AUTOSAR XML (schema 4.0)
standard types defined: float32, float64, sint16, sint32, sint8, uint16, uint32, uint8, void, boolean
package /ImplDataTypes
  impl type Impl_IOPositionSensorRead: implementation-data-type=uint8, type-emitter=RTE
  impl type Impl_IOWeightSensorRead: implementation-data-type=uint16, type-emitter=RTE
  impl type Impl_StepMotorStepSize: implementation-data-type=uint8, type-emitter=RTE
package /MappingSets
  data type mapping set MappingSet
package /PortInterfaces/ClientServer
  20 x client server interface:
    CsIf_HeightMotor
      operation Opr_IOSetForward
        arg Step: type=Impl_StepMotorStepSize, direction=IN
      operation Opr_IOSetReverse
        arg Step: type=Impl_StepMotorStepSize, direction=IN
    CsIf_HeightMotorSeatManager
      operation Opr_GetPosition
        arg Arg_Position: type=Impl_IOPositionSensorRead, direction=IN
    CsIf_HeightSensor
      operation Opr_HeightSensorGetPosition
        arg Position: type=Impl_IOPositionSensorRead, direction=OUT
    CsIf_IOHwAbsHeight
      operation Opr_HeightSensorGetPosition
        arg Arg_Height: type=Impl_IOPositionSensorRead, direction=OUT
    CsIf_IOHwAbsHeightMotor
      operation Opr_HeightMotorForward
    CsIf_IOHwAbsHeightMotorReverse
      operation Opr_HeightMotorReverse
    CsIf_IOHwAbsIncline
      operation Opr_IOHwAbsIncline
        arg Arg_Incline: type=Impl_IOPositionSensorRead, direction=OUT
    CsIf_IOHwAbsInclineMotor
      operation Opr_InclineMotorForward
    CsIf_IOHwAbsInclineMotorReverse
      operation Opr_InclineMotorReverse
    CsIf_IOHwAbsSlide
      operation Opr_IOHwAbsSlide
        arg Arg_Slide: type=Impl_IOPositionSensorRead, direction=OUT
    CsIf_IOHwAbsSlideMotor
      operation Opr_SLideMotorForward
    CsIf_IOHwAbsSlideMotorReverse
      operation Opr_SlideMotorReverse
    CsIf_IOHwAbsWeight
      operation Opr_GetWeight
        arg Arg_Weight: type=Impl_IOWeightSensorRead, direction=OUT
    CsIf_InclineMotor
      operation Opr_InclineMotorIOSetForward
        arg Step: type=Impl_StepMotorStepSize, direction=IN
      operation Opr_InclineMotorIOSetReverse
        arg Step: type=Impl_StepMotorStepSize, direction=IN
    CsIf_InclineMotorSeatManager
      operation Opr_GetPosition
        arg Arg_Position: type=Impl_IOPositionSensorRead, direction=IN
    CsIf_InclineSensor
      operation Opr_InclineSensorGetPosition
        arg Arg_Position: type=uint8, direction=OUT
    CsIf_SlideMotor
      operation Opr_SlideMotorSetReverse
        arg Step: type=Impl_StepMotorStepSize, direction=IN
      operation Opr_SlideMotor_SetForrward
        arg Step: type=Impl_StepMotorStepSize, direction=IN
    CsIf_SlideMotorSeatManager
      operation Opr_GetPositon
        arg Arg_Position: type=Impl_IOPositionSensorRead, direction=IN
    CsIf_SlideSensor
      operation Opr_GetPositon
        arg Position: type=uint8, direction=OUT
    CsIf_WeightSensor
      operation Opr_GetWeight
        arg Arg_weight: type=uint16, direction=OUT
package /SoftwareComponents
  9 x swc implementation, all with programming-language=C, sw-version=1.0.0, vendor-id=255:
    Impl_SWC_HeightMotor: behavior=Ibhv_SWC_HeightMotor
      code-descriptors:
        code Code: artifact-descriptors=autosar-engineering-object={short-label=SWC.c, category=SWSRC}
      resource consumption ResourceConsumption
    Impl_SWC_HeightSensor: behavior=Ibhv_SWC_HeightSensor
      code-descriptors:
        code Code: artifact-descriptors=autosar-engineering-object={short-label=SWC.c, category=SWSRC}
      resource consumption ResourceConsumption
    Impl_SWC_IOHwAbs: behavior=Ibhv_SWC_IOHwAbs
      code-descriptors:
        code Code: artifact-descriptors=autosar-engineering-object={short-label=SWC.c, category=SWSRC}
      resource consumption ResourceConsumption
    Impl_SWC_InclineMotor: behavior=Ibhv_SWC_InclineMotor
      code-descriptors:
        code Code: artifact-descriptors=autosar-engineering-object={short-label=SWC.c, category=SWSRC}
      resource consumption ResourceConsumption
    Impl_SWC_InclineSensor: behavior=Ibhv_SWC_InclineSensor
      code-descriptors:
        code Code: artifact-descriptors=autosar-engineering-object={short-label=SWC.c, category=SWSRC}
      resource consumption ResourceConsumption
    Impl_SWC_SeatManager: behavior=Ibhv_SWC_SeatManager
      code-descriptors:
        code Code: artifact-descriptors=autosar-engineering-object={short-label=SWC.c, category=SWSRC}
      resource consumption ResourceConsumption
    Impl_SWC_SlideMotor: behavior=Ibhv_SWC_SlideMotor
      code-descriptors:
        code Code: artifact-descriptors=autosar-engineering-object={short-label=SWC.c, category=SWSRC}
      resource consumption ResourceConsumption
    Impl_SWC_SlideSensor: behavior=Ibhv_SWC_SlideSensor
      code-descriptors:
        code Code: artifact-descriptors=autosar-engineering-object={short-label=SWC.c, category=SWSRC}
      resource consumption ResourceConsumption
    Impl_SWC_WeightSensor: behavior=Ibhv_SWC_WeightSensor
      code-descriptors:
        code Code: artifact-descriptors=autosar-engineering-object={short-label=SWC.c, category=SWSRC}
      resource consumption ResourceConsumption
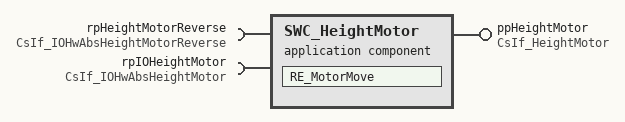
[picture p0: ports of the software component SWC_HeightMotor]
  application sw component type SWC_HeightMotor
    provide port ppHeightMotor: provided-interface=CsIf_HeightMotor
    require port rpHeightMotorReverse: required-interface=CsIf_IOHwAbsHeightMotorReverse
    require port rpIOHeightMotor: required-interface=CsIf_IOHwAbsHeightMotor
    behavior Ibhv_SWC_HeightMotor: data-type-mapping=MappingSet, handle-termination-and-restart=NO-SUPPORT
      operation invoked event OIE_ppHeightMotor_Opr_IOSetForward: start-on-event=RE_MotorMove, operation=ppHeightMotor.Opr_IOSetForward
      operation invoked event OIE_ppHeightMotor_Opr_IOSetReverse: start-on-event=RE_MotorMove, operation=ppHeightMotor.Opr_IOSetReverse
      runnable RE_MotorMove
        sync call SCP_rpHeightMotorReverse_Opr_HeightMotorReverse: operation=rpHeightMotorReverse.Opr_HeightMotorReverse, timeout=0.0
        sync call SCP_rpIOHeightMotor_Opr_HeightMotorForward: operation=rpIOHeightMotor.Opr_HeightMotorForward, timeout=0.0
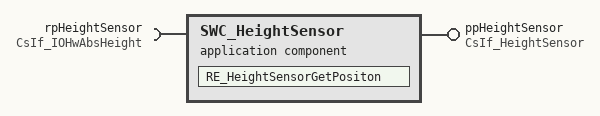
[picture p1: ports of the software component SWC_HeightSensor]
  application sw component type SWC_HeightSensor
    provide port ppHeightSensor: provided-interface=CsIf_HeightSensor
    require port rpHeightSensor: required-interface=CsIf_IOHwAbsHeight
    behavior Ibhv_SWC_HeightSensor: data-type-mapping=MappingSet, handle-termination-and-restart=NO-SUPPORT
      operation invoked event OIE_ppHeightSensor_Opr_HeightSensorGetPosition: start-on-event=Ibhv_SWC_HeightSensor/RE_HeightSensorGetPositon, operation=ppHeightSensor.Opr_HeightSensorGetPosition
      runnable RE_HeightSensorGetPositon
        sync call SCP_rpHeightSensor_Opr_GetHeight: operation=rpHeightSensor.Opr_HeightSensorGetPosition, timeout=0.0
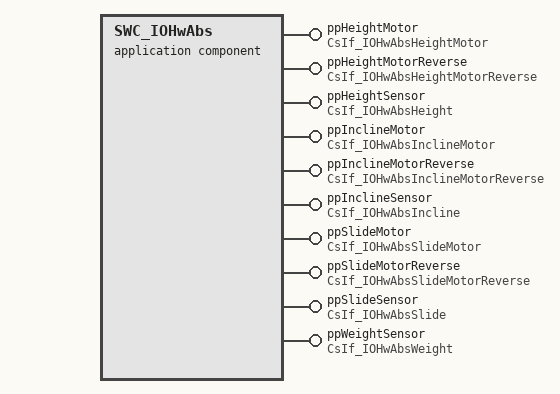
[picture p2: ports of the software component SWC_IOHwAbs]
  application sw component type SWC_IOHwAbs
    10 x provide port:
      ppHeightMotor: provided-interface=CsIf_IOHwAbsHeightMotor
      ppHeightMotorReverse: provided-interface=CsIf_IOHwAbsHeightMotorReverse
      ppHeightSensor: provided-interface=CsIf_IOHwAbsHeight
      ppInclineMotor: provided-interface=CsIf_IOHwAbsInclineMotor
      ppInclineMotorReverse: provided-interface=CsIf_IOHwAbsInclineMotorReverse
      ppInclineSensor: provided-interface=CsIf_IOHwAbsIncline
      ppSlideMotor: provided-interface=CsIf_IOHwAbsSlideMotor
      ppSlideMotorReverse: provided-interface=CsIf_IOHwAbsSlideMotorReverse
      ppSlideSensor: provided-interface=CsIf_IOHwAbsSlide
      ppWeightSensor: provided-interface=CsIf_IOHwAbsWeight
    behavior Ibhv_SWC_IOHwAbs: data-type-mapping=MappingSet, handle-termination-and-restart=NO-SUPPORT
      10 x operation invoked event:
        OIE_ppHeightMotorReverse_Opr_HeightMotorReverse: start-on-event=RE_HeightMotorSetReverse, operation=ppHeightMotorReverse.Opr_HeightMotorReverse
        OIE_ppHeightMotor_Opr_HeightMotorForward: start-on-event=RE_HeightMotorSetForward, operation=ppHeightMotor.Opr_HeightMotorForward
        OIE_ppHeightSensor_Opr_HeightSensorGetPosition: start-on-event=Ibhv_SWC_IOHwAbs/RE_HeightSensorGetPositon, operation=ppHeightSensor.Opr_HeightSensorGetPosition
        OIE_ppInclineMotorReverse_Opr_InclineMotorReverse: start-on-event=RE_InclineMotorSetReverse, operation=ppInclineMotorReverse.Opr_InclineMotorReverse
        OIE_ppInclineMotor_Opr_InclineMotorForward: start-on-event=RE_InclineMotorSetForward, operation=ppInclineMotor.Opr_InclineMotorForward
        OIE_ppInclineSensor_Opr_IOHwAbsIncline: start-on-event=RE_InclineSensorGetPosition, operation=ppInclineSensor.Opr_IOHwAbsIncline
        OIE_ppSlideMotorReverse_Opr_SlideMotorReverse: start-on-event=RE_SlideMotorSetReverse, operation=ppSlideMotorReverse.Opr_SlideMotorReverse
        OIE_ppSlideMotor_Opr_SLideMotorForward: start-on-event=RE_SlideMotorSetForward, operation=ppSlideMotor.Opr_SLideMotorForward
        OIE_ppSlideSensor_Opr_IOHwAbsSlide: start-on-event=RE_SlideSensorGetPosition, operation=ppSlideSensor.Opr_IOHwAbsSlide
        OIE_ppWeightSensor_Opr_GetWeight: start-on-event=RE_IoHwAbsGetWeight, operation=ppWeightSensor.Opr_GetWeight
      10 x runnable:
        RE_HeightMotorSetForward
        RE_HeightMotorSetReverse
        RE_HeightSensorGetPositon
        RE_InclineMotorSetForward
        RE_InclineMotorSetReverse
        RE_InclineSensorGetPosition
        RE_IoHwAbsGetWeight
        RE_SlideMotorSetForward
        RE_SlideMotorSetReverse
        RE_SlideSensorGetPosition
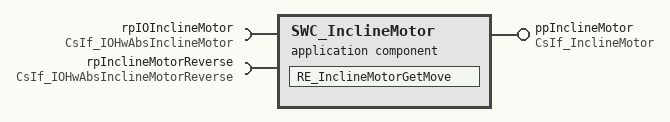
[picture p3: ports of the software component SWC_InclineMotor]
  application sw component type SWC_InclineMotor
    provide port ppInclineMotor: provided-interface=CsIf_InclineMotor
    require port rpIOInclineMotor: required-interface=CsIf_IOHwAbsInclineMotor
    require port rpInclineMotorReverse: required-interface=CsIf_IOHwAbsInclineMotorReverse
    behavior Ibhv_SWC_InclineMotor: data-type-mapping=MappingSet, handle-termination-and-restart=NO-SUPPORT
      operation invoked event OIE_ppInclineMotor_Opr_InclineMotorIOSetForward: start-on-event=RE_InclineMotorGetMove, operation=ppInclineMotor.Opr_InclineMotorIOSetForward
      operation invoked event OIE_ppInclineMotor_Opr_InclineMotorIOSetReverse: start-on-event=RE_InclineMotorGetMove, operation=ppInclineMotor.Opr_InclineMotorIOSetReverse
      runnable RE_InclineMotorGetMove
        sync call SCP_rpIOInclineMotor_Opr_InclineMotorForward: operation=rpIOInclineMotor.Opr_InclineMotorForward, timeout=0.0
        sync call SCP_rpInclineMotorReverse_Opr_InclineMotorReverse: operation=rpInclineMotorReverse.Opr_InclineMotorReverse, timeout=0.0
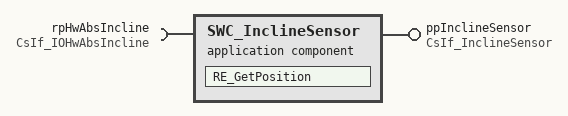
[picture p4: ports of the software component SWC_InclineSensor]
  application sw component type SWC_InclineSensor
    provide port ppInclineSensor: provided-interface=CsIf_InclineSensor
    require port rpHwAbsIncline: required-interface=CsIf_IOHwAbsIncline
    behavior Ibhv_SWC_InclineSensor: data-type-mapping=MappingSet, handle-termination-and-restart=NO-SUPPORT
      operation invoked event OIE_ppInclineSensor_Opr_InclineSensorGetPosition: start-on-event=Ibhv_SWC_InclineSensor/RE_GetPosition, operation=ppInclineSensor.Opr_InclineSensorGetPosition
      runnable RE_GetPosition
        sync call SCP_rpHwAbsIncline_Opr_IOHwAbsIncline: operation=rpHwAbsIncline.Opr_IOHwAbsIncline, timeout=0.0
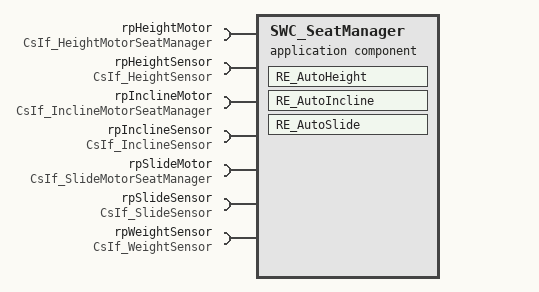
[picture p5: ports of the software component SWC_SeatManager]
  application sw component type SWC_SeatManager
    7 x require port:
      rpHeightMotor: required-interface=CsIf_HeightMotorSeatManager
      rpHeightSensor: required-interface=CsIf_HeightSensor
      rpInclineMotor: required-interface=CsIf_InclineMotorSeatManager
      rpInclineSensor: required-interface=CsIf_InclineSensor
      rpSlideMotor: required-interface=CsIf_SlideMotorSeatManager
      rpSlideSensor: required-interface=CsIf_SlideSensor
      rpWeightSensor: required-interface=CsIf_WeightSensor
    behavior Ibhv_SWC_SeatManager: data-type-mapping=MappingSet, handle-termination-and-restart=NO-SUPPORT
      runnable RE_AutoHeight
        sync call SCP_rpHeightMotor_Opr_GetPosition: operation=rpHeightMotor.Opr_GetPosition, timeout=0.0
        sync call SCP_rpHeightSensor_Opr_HeightSensorGetPosition: operation=rpHeightSensor.Opr_HeightSensorGetPosition, timeout=0.0
        sync call SCP_rpWeightSensor_Opr_GetWeight: operation=rpWeightSensor.Opr_GetWeight, timeout=0.0
      runnable RE_AutoIncline
        sync call SCP_rpInclineMotor_Opr_GetPosition: operation=rpInclineMotor.Opr_GetPosition, timeout=0.0
        sync call SCP_rpInclineSensor_Opr_Position: operation=rpInclineSensor.Opr_InclineSensorGetPosition, timeout=0.0
        sync call SCP_rpWeightSensor_Opr_GetWeight: operation=rpWeightSensor.Opr_GetWeight, timeout=0.0
      runnable RE_AutoSlide
        sync call SCP_rpSlideMotor_Opr_GetPositon: operation=rpSlideMotor.Opr_GetPositon, timeout=0.0
        sync call SCP_rpSlideSensor_Opr_GetPositon: operation=rpSlideSensor.Opr_GetPositon, timeout=0.0
        sync call SCP_rpWeightSensor_Opr_GetWeight: operation=rpWeightSensor.Opr_GetWeight, timeout=0.0
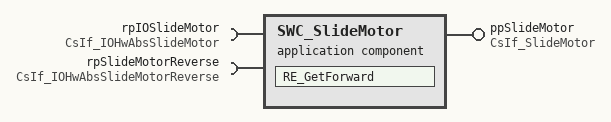
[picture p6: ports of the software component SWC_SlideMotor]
  application sw component type SWC_SlideMotor
    provide port ppSlideMotor: provided-interface=CsIf_SlideMotor
    require port rpIOSlideMotor: required-interface=CsIf_IOHwAbsSlideMotor
    require port rpSlideMotorReverse: required-interface=CsIf_IOHwAbsSlideMotorReverse
    behavior Ibhv_SWC_SlideMotor: data-type-mapping=MappingSet, handle-termination-and-restart=NO-SUPPORT
      operation invoked event OIE_ppSlideMotor_Opr_SlideMotorSetReverse: start-on-event=RE_GetForward, operation=ppSlideMotor.Opr_SlideMotorSetReverse
      operation invoked event OIE_ppSlideMotor_Opr_SlideMotor_SetForrward: start-on-event=RE_GetForward, operation=ppSlideMotor.Opr_SlideMotor_SetForrward
      runnable RE_GetForward
        sync call SCP_rpIOSlideMotor_Opr_SLideMotorForward: operation=rpIOSlideMotor.Opr_SLideMotorForward, timeout=0.0
        sync call SCP_rpSlideMotorReverse_Opr_SlideMotorReverse: operation=rpSlideMotorReverse.Opr_SlideMotorReverse, timeout=0.0
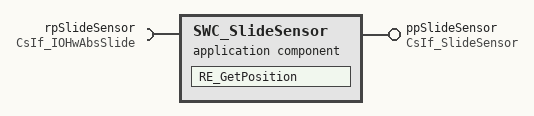
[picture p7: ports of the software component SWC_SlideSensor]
  application sw component type SWC_SlideSensor
    provide port ppSlideSensor: provided-interface=CsIf_SlideSensor
    require port rpSlideSensor: required-interface=CsIf_IOHwAbsSlide
    behavior Ibhv_SWC_SlideSensor: data-type-mapping=MappingSet, handle-termination-and-restart=NO-SUPPORT
      operation invoked event OIE_ppSlideSensor_Opr_GetPositon: start-on-event=Ibhv_SWC_SlideSensor/RE_GetPosition, operation=ppSlideSensor.Opr_GetPositon
      runnable RE_GetPosition
        sync call SCP_rpSlideSensor_Opr_IOHwAbsSlide: operation=rpSlideSensor.Opr_IOHwAbsSlide, timeout=0.0
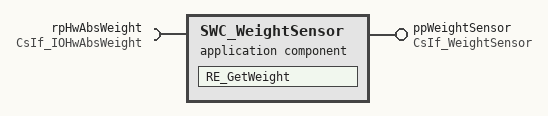
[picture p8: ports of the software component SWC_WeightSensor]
  application sw component type SWC_WeightSensor
    provide port ppWeightSensor: provided-interface=CsIf_WeightSensor
    require port rpHwAbsWeight: required-interface=CsIf_IOHwAbsWeight
    behavior Ibhv_SWC_WeightSensor: data-type-mapping=MappingSet, handle-termination-and-restart=NO-SUPPORT
      operation invoked event OIE_ppWeightSensor_Opr_GetWeight: start-on-event=RE_GetWeight, operation=ppWeightSensor.Opr_GetWeight
      runnable RE_GetWeight
        sync call SCP_rpHwAbsWeight_Opr_GetWeight: operation=rpHwAbsWeight.Opr_GetWeight, timeout=0.0
package /Compositions
  composition sw component type TestApp5Composition
    9 x component:
      SWC_HeightMotor: type=SWC_HeightMotor
      SWC_HeightSensor: type=SWC_HeightSensor
      SWC_IOHwAbs: type=SWC_IOHwAbs
      SWC_InclineMotor: type=SWC_InclineMotor
      SWC_InclineSensor: type=SWC_InclineSensor
      SWC_SeatManager: type=SWC_SeatManager
      SWC_SlideMotor: type=SWC_SlideMotor
      SWC_SlideSensor: type=SWC_SlideSensor
      SWC_WeightSensor: type=SWC_WeightSensor
    connect SWC_HeightMotor.ppHeightMotor -> SWC_SeatManager.rpHeightMotor
    connect SWC_HeightSensor.ppHeightSensor -> SWC_SeatManager.rpHeightSensor
    connect SWC_IOHwAbs.ppHeightMotorReverse -> SWC_HeightMotor.rpHeightMotorReverse
    connect SWC_IOHwAbs.ppHeightMotor -> SWC_HeightMotor.rpIOHeightMotor
    connect SWC_IOHwAbs.ppHeightSensor -> SWC_HeightSensor.rpHeightSensor
    connect SWC_IOHwAbs.ppInclineMotorReverse -> SWC_InclineMotor.rpInclineMotorReverse
    connect SWC_IOHwAbs.ppInclineMotor -> SWC_InclineMotor.rpIOInclineMotor
    connect SWC_IOHwAbs.ppInclineSensor -> SWC_InclineSensor.rpHwAbsIncline
    connect SWC_IOHwAbs.ppSlideMotor -> SWC_SlideMotor.rpIOSlideMotor
    connect SWC_IOHwAbs.ppSlideMotor -> SWC_SlideMotor.rpSlideMotorReverse
    connect SWC_IOHwAbs.ppSlideSensor -> SWC_SlideSensor.rpSlideSensor
    connect SWC_IOHwAbs.ppWeightSensor -> SWC_WeightSensor.rpHwAbsWeight
    connect SWC_InclineMotor.ppInclineMotor -> SWC_SeatManager.rpInclineMotor
    connect SWC_InclineSensor.ppInclineSensor -> SWC_SeatManager.rpInclineSensor
    connect SWC_SlideMotor.ppSlideMotor -> SWC_SeatManager.rpSlideMotor
    connect SWC_SlideSensor.ppSlideSensor -> SWC_SeatManager.rpSlideSensor
    connect SWC_WeightSensor.ppWeightSensor -> SWC_SeatManager.rpWeightSensor
